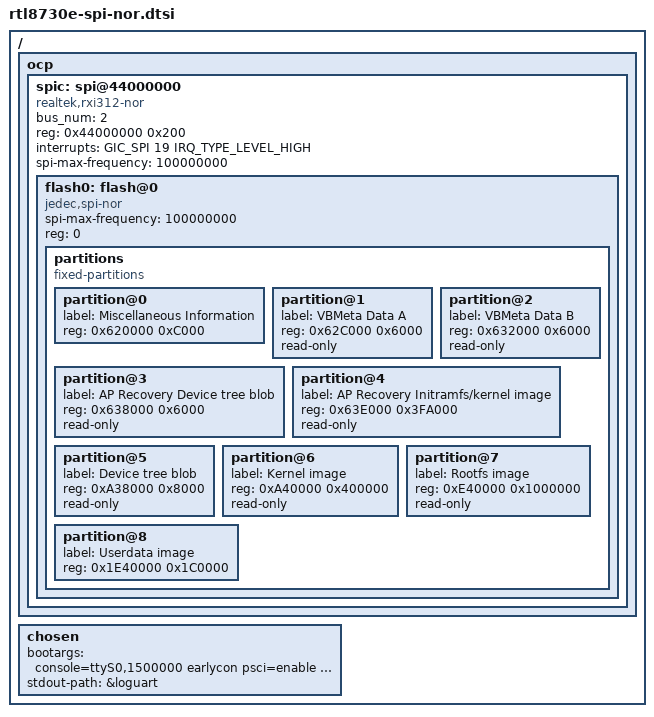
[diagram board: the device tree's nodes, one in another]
// SPDX-License-Identifier: GPL-2.0-only
/*
* Realtek DTS for SPI NOR flash
*
* Copyright (C) 2023, Realtek Corporation. All rights reserved.
*/

/ {
	ocp {
		spic: spi@44000000 {
			compatible = "realtek,rxi312-nor";
			#address-cells = <1>;
			#size-cells = <0>;
			bus_num = <2>;
			reg = <0x44000000 0x200>;
			interrupts = <GIC_SPI 19 IRQ_TYPE_LEVEL_HIGH>;
			spi-max-frequency = <100000000>;

			flash0: flash@0 {
				#address-cells = <1>;
				#size-cells = <1>;
				compatible = "jedec,spi-nor";
				spi-max-frequency = <100000000>;
				reg = <0>;

				partitions {
					compatible = "fixed-partitions";
					#address-cells = <1>;
					#size-cells = <1>;

					partition@0 {
						label = "Miscellaneous Information";
						reg = <0x620000 0xC000>;
					};
					partition@1 {
						label = "VBMeta Data A";
						reg = <0x62C000 0x6000>;
						read-only;
					};
					partition@2 {
						label = "VBMeta Data B";
						reg = <0x632000 0x6000>;
						read-only;
					};
					partition@3 {
						label = "AP Recovery Device tree blob";
						reg = <0x638000 0x6000>;
						read-only;
					};
					partition@4 {
						label = "AP Recovery Initramfs/kernel image";
						reg = <0x63E000 0x3FA000>;
						read-only;
					};
					partition@5 {
						label = "Device tree blob";
						reg = <0xA38000 0x8000>;
						read-only;
					};
					partition@6 {
						label = "Kernel image";
						reg = <0xA40000 0x400000>;
						read-only;
					};
					partition@7 {
						label = "Rootfs image";
						reg = <0xE40000 0x1000000>;
						read-only;
					};
					partition@8 {
						label = "Userdata image";
						reg = <0x1E40000 0x1C0000>;
					};

				};
			};
		};
	};

	chosen {
		bootargs = "console=ttyS0,1500000 earlycon psci=enable root=/dev/mtdblock7 rootfstype=squashfs";
		stdout-path = &loguart;
	};

};
